# ATSAMC20N18A register map
Vendor: Atmel Corporation; Series: SAMC20; File version: A
CPU: CM0+ r0p1, little endian, MPU, no FPU, VTOR, 2 interrupt priority bits
Registers are 32-bit, read-write, reset 0x0 unless marked. A register's access mark holds for its fields unless they carry their own. Offsets are from the block's base; [hi:lo] are bit positions; {n}, {i} and the like mark numbered series; 'fields as' and 'values as' point back to an identical list.

## MTB — Cortex-M0+ Micro-Trace Buffer
Base 0x41008000; register names take the prefix MTB_
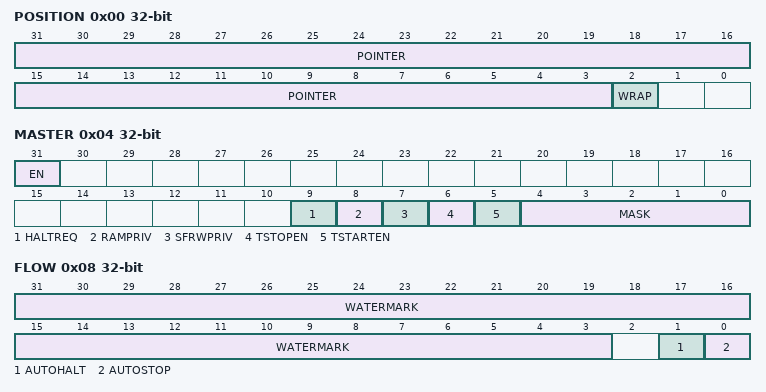
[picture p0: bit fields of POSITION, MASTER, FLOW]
0x00 POSITION — MTB Position
  [31:3] POINTER — Trace Packet Location Pointer
  [2] WRAP — Pointer Value Wraps
0x04 MASTER — MTB Master
  [31] EN — Main Trace Enable
  [9] HALTREQ — Halt Request
  [8] RAMPRIV — SRAM Privilege
  [7] SFRWPRIV — Special Function Register Write Privilege
  [6] TSTOPEN — Trace Stop Input Enable
  [5] TSTARTEN — Trace Start Input Enable
  [4:0] MASK — Maximum Value of the Trace Buffer in SRAM
0x08 FLOW — MTB Flow
  [31:3] WATERMARK — Watermark value
  [1] AUTOHALT — Auto Halt Request
  [0] AUTOSTOP — Auto Stop Tracing
0x0C BASE ro — MTB Base
0xF00 ITCTRL — MTB Integration Mode Control
0xFA0 CLAIMSET — MTB Claim Set
0xFA4 CLAIMCLR — MTB Claim Clear
0xFB0 LOCKACCESS — MTB Lock Access
0xFB4 LOCKSTATUS ro — MTB Lock Status
0xFB8 AUTHSTATUS ro — MTB Authentication Status
0xFBC DEVARCH ro — MTB Device Architecture
0xFC8 DEVID ro — MTB Device Configuration
0xFCC DEVTYPE ro — MTB Device Type
{0xFC0+4i} PID{i} ro (i=4..7) — Peripheral Identification {i}
{0xFE0+4i} PID{i} ro (i=0..3) — Peripheral Identification {i}
{0xFF0+4i} CID{i} ro (i=0..3) — Component Identification {i}

## OSCCTRL — Oscillators Control
Base 0x40001000; register names take the prefix OSCCTRL_
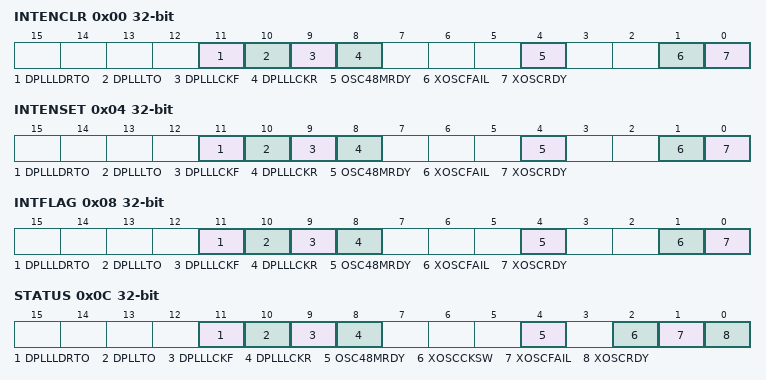
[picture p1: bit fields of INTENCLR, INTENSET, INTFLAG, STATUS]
0x00 INTENCLR — Interrupt Enable Clear
  [11] DPLLLDRTO — DPLL Ratio Ready Interrupt Enable
  [10] DPLLLTO — DPLL Time Out Interrupt Enable
  [9] DPLLLCKF — DPLL Lock Fall Interrupt Enable
  [8] DPLLLCKR — DPLL Lock Rise Interrupt Enable
  [4] OSC48MRDY — OSC48M Ready Interrupt Enable
  [1] XOSCFAIL — XOSC Clock Failure Detector Interrupt Enable
  [0] XOSCRDY — XOSC Ready Interrupt Enable
0x04 INTENSET — Interrupt Enable Set
  fields as INTENCLR
0x08 INTFLAG — Interrupt Flag Status and Clear
  [11] DPLLLDRTO — DPLL Ratio Ready
  [10] DPLLLTO — DPLL Timeout
  [9] DPLLLCKF — DPLL Lock Fall
  [8] DPLLLCKR — DPLL Lock Rise
  [4] OSC48MRDY — OSC48M Ready
  [1] XOSCFAIL — XOSC Clock Failure Detector
  [0] XOSCRDY — XOSC Ready
0x0C STATUS ro — Power and Clocks Status
  [11] DPLLLDRTO — DPLL Ratio Ready
  [10] DPLLTO — DPLL Timeout
  [9] DPLLLCKF — DPLL Lock Fall
  [8] DPLLLCKR — DPLL Lock Rise
  [4] OSC48MRDY — OSC48M Ready
  [2] XOSCCKSW — XOSC Clock Switch
  [1] XOSCFAIL — XOSC Clock Failure Detector
  [0] XOSCRDY — XOSC Ready
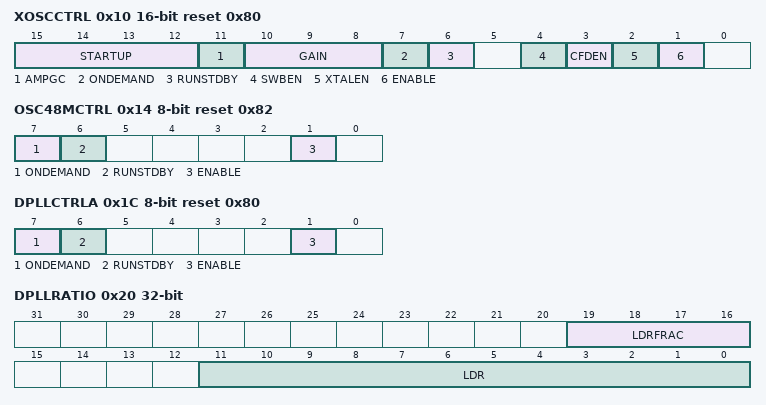
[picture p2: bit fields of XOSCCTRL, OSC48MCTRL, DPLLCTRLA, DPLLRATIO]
0x10 XOSCCTRL 16-bit reset 0x80 — External Multipurpose Crystal Oscillator (XOSC) Control
  [15:12] STARTUP — Start-Up Time
  [11] AMPGC — Automatic Amplitude Gain Control
  [10:8] GAIN — Oscillator Gain
  [7] ONDEMAND — On Demand Control
  [6] RUNSTDBY — Run in Standby
  [4] SWBEN — Xosc Clock Switch Enable
  [3] CFDEN — Xosc Clock Failure Detecteor Enable
  [2] XTALEN — Crystal Oscillator Enable
  [1] ENABLE — Oscillator Enable
0x12 CFDPRESC 8-bit — Cloc Failure Detector Prescaler
  [2:0] CFDPRESC — Clock Failure Detector Prescaler
0x13 EVCTRL 8-bit — Event Control
  [0] CFDEO — Clock Failure Detector Event Output Enable
0x14 OSC48MCTRL 8-bit reset 0x82 — 48MHz Internal Oscillator (OSC48M) Control
  [7] ONDEMAND — On Demand Control
  [6] RUNSTDBY — Run in Standby
  [1] ENABLE — Oscillator Enable
0x15 OSC48MDIV 8-bit reset 0xB — OSC48M Divider
  [3:0] DIV — OSC48M Division Factor
0x16 OSC48MSTUP 8-bit reset 0x7 — OSC48M Startup Time
  [2:0] STARTUP — Startup Time
0x18 OSC48MSYNCBUSY ro — OSC48M Synchronization Busy
  [2] OSC48MDIV — OSC48MDIV Synchronization Status
0x1C DPLLCTRLA 8-bit reset 0x80 — DPLL Control
  [7] ONDEMAND
  [6] RUNSTDBY — Run in Standby
  [1] ENABLE
0x20 DPLLRATIO — DPLL Ratio Control
  [19:16] LDRFRAC — Loop Divider Ratio Fractional Part
  [11:0] LDR — Loop Divider Ratio
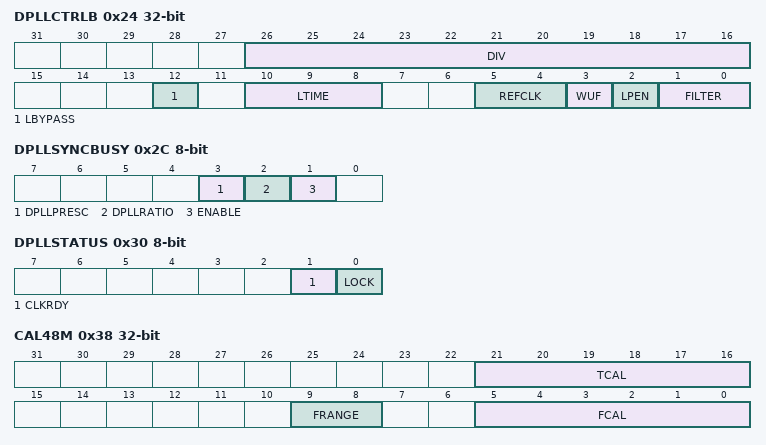
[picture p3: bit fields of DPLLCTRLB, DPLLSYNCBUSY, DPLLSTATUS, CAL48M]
0x24 DPLLCTRLB — Digital Core Configuration
  [26:16] DIV — Clock Divider
  [12] LBYPASS — Lock Bypass
  [10:8] LTIME — Lock Time
  [5:4] REFCLK — Reference Clock Selection
  [3] WUF — Wake Up Fast
  [2] LPEN — Low-Power Enable
  [1:0] FILTER — Proportional Integral Filter Selection
0x28 DPLLPRESC 8-bit — DPLL Prescaler
  [1:0] PRESC — Output Clock Prescaler
    0=DIV1 (DPLL output is divided by 1); 1=DIV2 (DPLL output is divided by 2); 2=DIV4 (DPLL output is divided by 4)
0x2C DPLLSYNCBUSY 8-bit ro — DPLL Synchronization Busy
  [3] DPLLPRESC — DPLL Prescaler Synchronization Status
  [2] DPLLRATIO — DPLL Ratio Synchronization Status
  [1] ENABLE — DPLL Enable Synchronization Status
0x30 DPLLSTATUS 8-bit ro
  [1] CLKRDY — DPLL Clock Ready
  [0] LOCK — DPLL Lock Status
0x38 CAL48M — 48MHz Oscillator Calibration
  [21:16] TCAL — Temperature Calibration (48MHz)
  [9:8] FRANGE — Frequency Range (48MHz)
  [5:0] FCAL — Frequency Calibration (48MHz)

## Notices in the file
Atmel Microcontroller Software Support
Copyright (c) 2017 Atmel Corporation,
a wholly owned subsidiary of Microchip Technology Inc.
Licensed under the Apache License, Version 2.0 (the "License");
you may not use this file except in compliance with the License.
You may obtain a copy of the Licence at
http://www.apache.org/licenses/LICENSE-2.0
Unless required by applicable law or agreed to in writing, software
distributed under the License is distributed on an "AS IS" BASIS,
WITHOUT WARRANTIES OR CONDITIONS OF ANY KIND, either express or implied.
See the License for the specific language governing permissions and
limitations under the License.
